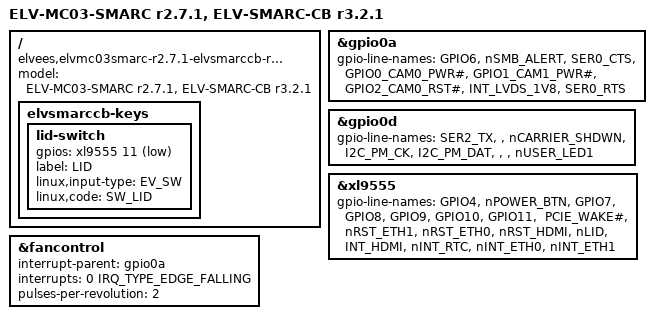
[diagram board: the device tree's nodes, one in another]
// SPDX-License-Identifier: GPL-2.0+
/*
 * Copyright 2024 RnD Center "ELVEES", JSC
 */

/dts-v1/;

#include "mcom03-elvmc03smarc-r2.6.1-elvsmarccb-r3.1.0.dts"

/ {
	model = "ELV-MC03-SMARC r2.7.1, ELV-SMARC-CB r3.2.1";
	compatible = "elvees,elvmc03smarc-r2.7.1-elvsmarccb-r3.2.1",
		     "elvees,elvmc03smarc-elvsmarccb",
		     "elvees,elvsmarccb-r3.2.1",
		     "elvees,elvsmarccb",
		     "elvees,elvmc03smarc-r2.7.1",
		     "elvees,elvmc03smarc",
		     "elvees,mcom03";

	elvsmarccb-keys {
		lid-switch {
			gpios = <&xl9555 11 GPIO_ACTIVE_LOW>;
			label = "LID";
			linux,input-type = <EV_SW>;
			linux,code = <SW_LID>;
		};
	};
};

&gpio0a {
	gpio-line-names = "GPIO6", "nSMB_ALERT", "SER0_CTS", "GPIO0_CAM0_PWR#",
		"GPIO1_CAM1_PWR#", "GPIO2_CAM0_RST#", "INT_LVDS_1V8", "SER0_RTS";
};

&gpio0d {
	gpio-line-names = "SER2_TX", "", "nCARRIER_SHDWN", "I2C_PM_CK",
		"I2C_PM_DAT", "", "", "nUSER_LED1";
};

&xl9555 {
	gpio-line-names = "GPIO4", "nPOWER_BTN", "GPIO7", "GPIO8", "GPIO9",
		"GPIO10", "GPIO11", " PCIE_WAKE#", "nRST_ETH1", "nRST_ETH0",
		"nRST_HDMI", "nLID", "INT_HDMI", "nINT_RTC", "nINT_ETH0", "nINT_ETH1";
};

&fancontrol {
	interrupt-parent = <&gpio0a>;
	interrupts = <0 IRQ_TYPE_EDGE_FALLING>;
	pulses-per-revolution = <2>;
};
